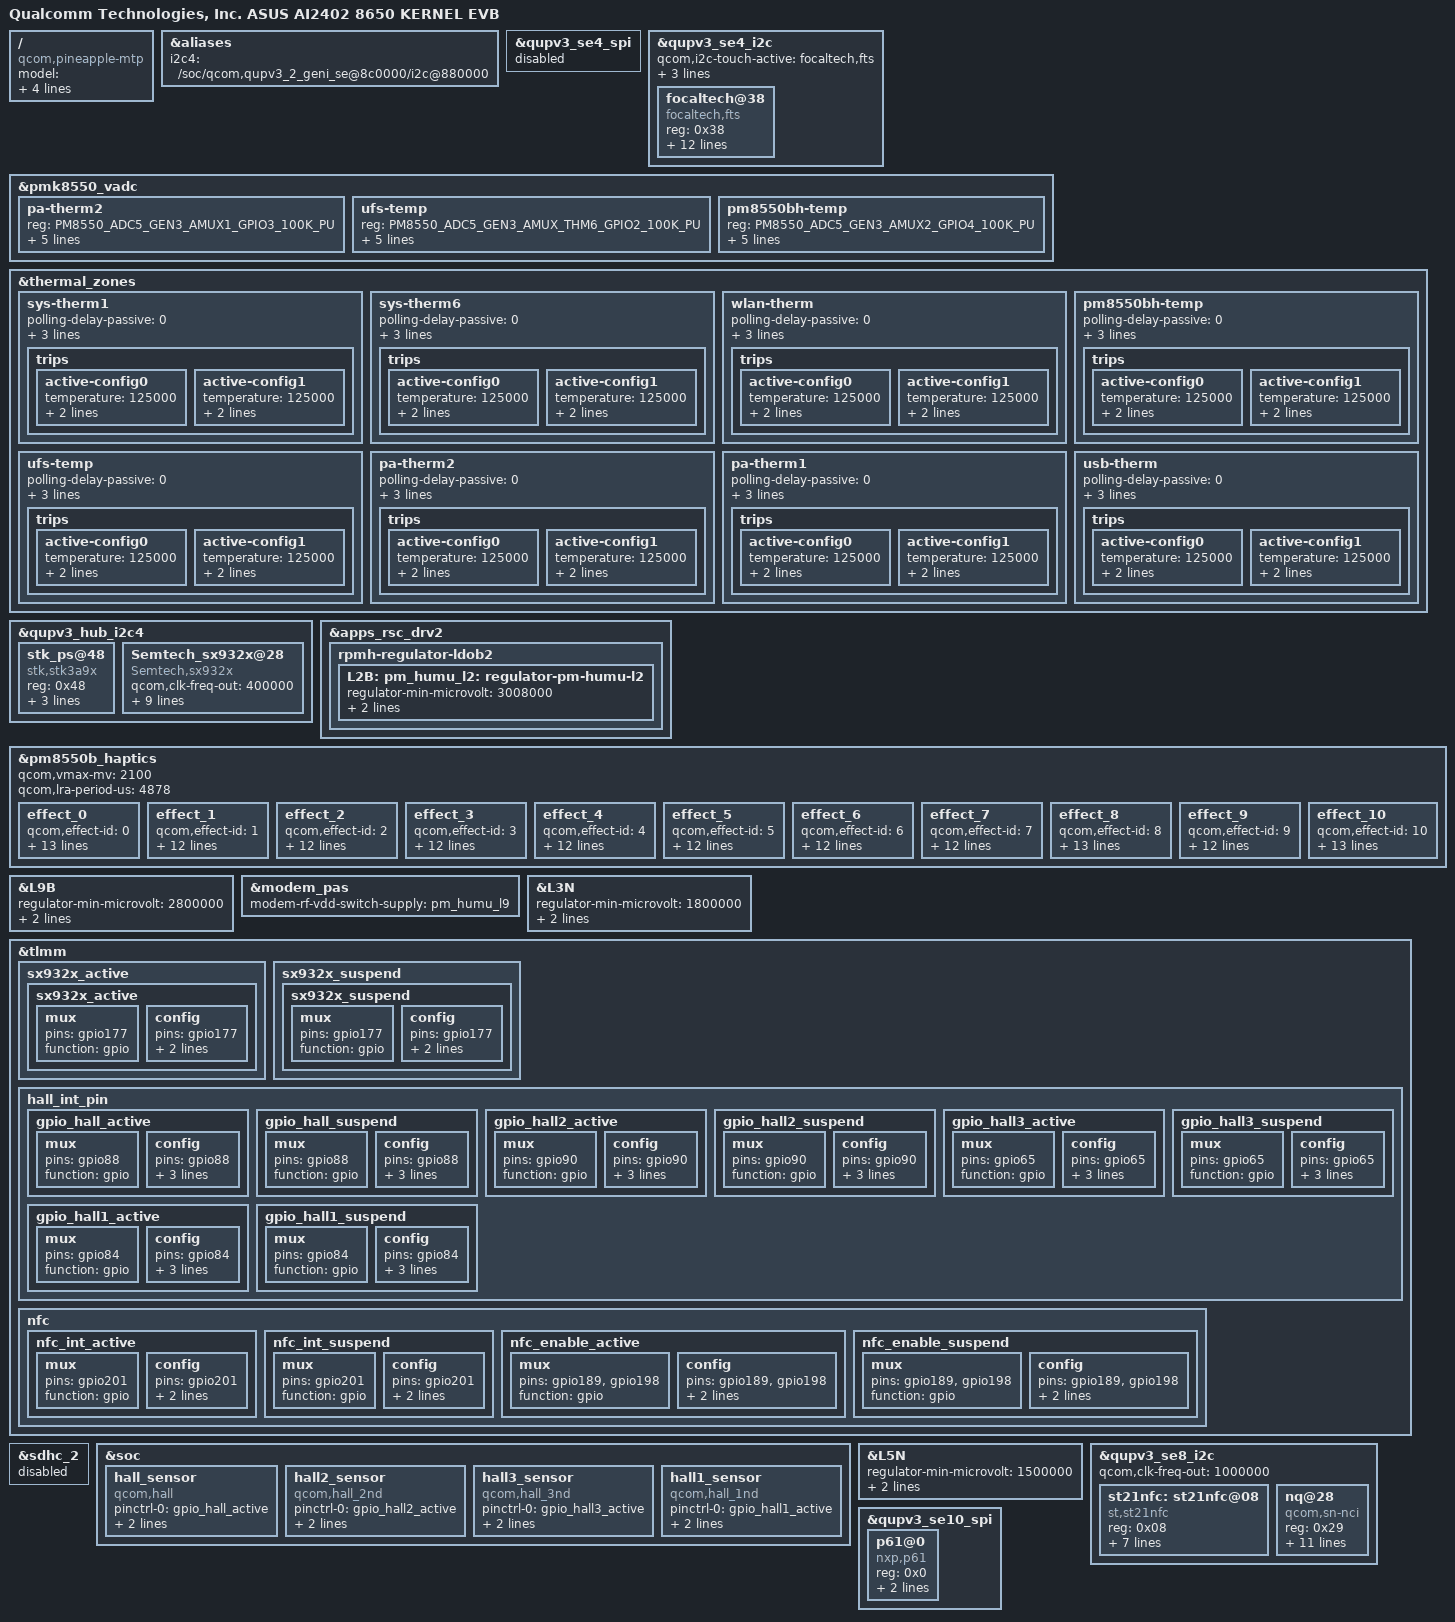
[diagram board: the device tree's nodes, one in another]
/dts-v1/;
/plugin/;

#include "pineapple-mtp.dtsi"

/ {
	model = "Qualcomm Technologies, Inc.  ASUS AI2402 8650 KERNEL EVB ";
	compatible = "qcom,pineapple-mtp", "qcom,pineapple", "qcom,pineapplep-mtp", "qcom,pineapplep", "qcom,mtp";
	qcom,msm-id = <557 0x10000>, <557 0x20000>, <577 0x10000>, <577 0x20000>;
	qcom,board-id = <38 0>;
};

&aliases {
		i2c4 = "/soc/qcom,qupv3_2_geni_se@8c0000/i2c@880000";
};

/*   ====================================
*    overlay for touch - start
*    ====================================
*/


&qupv3_se4_spi {
	status = "disable";
};

&qupv3_se4_i2c {
	#address-cells = <1>;
	#size-cells = <0>;

	status = "ok";
	qcom,i2c-touch-active = "focaltech,fts";
	qcom,touch-active = "focaltech,fts";
	qcom,la-vm;
	qcom,shared;

	focaltech@38 {
		compatible = "focaltech,fts";
		reg = <0x38>;
		interrupt-parent = <&tlmm>;
		interrupts = <162 0x2008>;
		focaltech,reset-gpio = <&tlmm 161 0x00>;
		focaltech,irq-gpio = <&tlmm 162 0x2008>;
		focaltech,max-touch-number = <10>;
		focaltech,display-coords = <0 0 1080 2400>;
		focaltech,touch-type = "primary";

		vdd-supply = <&L14B>;
		vcc_i2c-supply = <&L4B>;

		pinctrl-names = "pmx_ts_active", "pmx_ts_suspend","pmx_ts_release";
		pinctrl-0 = <&ts_active>;
		pinctrl-1 = <&ts_int_suspend &ts_reset_suspend>;
		pinctrl-2 = <&ts_release>;
		//panel = <&dsi_ams667uu07_fhd_plus_dsc_cmd &dsi_ams678_fhd_plus_dsc_cmd &dsi_ams678_er2_fhd_plus_dsc_cmd>
	};
};



&pmk8550_vadc {
	pa-therm2{
		reg = <PM8550_ADC5_GEN3_AMUX1_GPIO3_100K_PU>;
		label = "pa-therm2";
		qcom,ratiometric;
		qcom,hw-settle-time = <200>;
		qcom,pre-scaling = <1 1>;
		qcom,adc-tm-type = <1>;
	};

	ufs-temp {
		reg = <PM8550_ADC5_GEN3_AMUX_THM6_GPIO2_100K_PU>;
		label = "ufs-temp";
		qcom,ratiometric;
		qcom,hw-settle-time = <200>;
		qcom,pre-scaling = <1 1>;
		qcom,adc-tm-type = <1>;
	};

	pm8550bh-temp {
		reg = <PM8550_ADC5_GEN3_AMUX2_GPIO4_100K_PU>;
		label = "pm8550bh-temp";
		qcom,ratiometric;
		qcom,hw-settle-time = <200>;
		qcom,pre-scaling = <1 1>;
		qcom,adc-tm-type = <1>;
	};
};

&thermal_zones{
	sys-therm1 {
		polling-delay-passive = <0>;
		polling-delay = <0>;
		thermal-sensors = <&pmk8550_vadc PM8550_ADC5_GEN3_AMUX_THM1_100K_PU>;
		trips {
			active-config0 {
				temperature = <125000>;
				hysteresis = <1000>;
				type = "passive";
			};

			active-config1 {
				temperature = <125000>;
				hysteresis = <1000>;
				type = "passive";
			};
		};
	};

	sys-therm6 {
		polling-delay-passive = <0>;
		polling-delay = <0>;
		thermal-sensors = <&pmk8550_vadc PM8550_ADC5_GEN3_AMUX_THM2_100K_PU>;
		trips {
			active-config0 {
				temperature = <125000>;
				hysteresis = <1000>;
				type = "passive";
			};

			active-config1 {
				temperature = <125000>;
				hysteresis = <1000>;
				type = "passive";
			};
		};
	};

	wlan-therm {
		polling-delay-passive = <0>;
		polling-delay = <0>;
		thermal-sensors = <&pmk8550_vadc PM8550_ADC5_GEN3_AMUX_THM3_100K_PU>;
		trips {
			active-config0 {
				temperature = <125000>;
				hysteresis = <1000>;
				type = "passive";
			};

			active-config1 {
				temperature = <125000>;
				hysteresis = <1000>;
				type = "passive";
			};
		};
	};

	pm8550bh-temp {
		polling-delay-passive = <0>;
		polling-delay = <0>;
		thermal-sensors = <&pmk8550_vadc PM8550_ADC5_GEN3_AMUX2_GPIO4_100K_PU>;
		trips {
			active-config0 {
				temperature = <125000>;
				hysteresis = <1000>;
				type = "passive";
			};

			active-config1 {
				temperature = <125000>;
				hysteresis = <1000>;
				type = "passive";
			};
		};
	};

	ufs-temp {
		polling-delay-passive = <0>;
		polling-delay = <0>;
		thermal-sensors = <&pmk8550_vadc PM8550_ADC5_GEN3_AMUX_THM6_GPIO2_100K_PU>;
		trips {
			active-config0 {
				temperature = <125000>;
				hysteresis = <1000>;
				type = "passive";
			};

			active-config1 {
				temperature = <125000>;
				hysteresis = <1000>;
				type = "passive";
			};
		};
	};

	pa-therm2 {
		polling-delay-passive = <0>;
		polling-delay = <0>;
		thermal-sensors = <&pmk8550_vadc PM8550_ADC5_GEN3_AMUX1_GPIO3_100K_PU>;
		trips {
			active-config0 {
				temperature = <125000>;
				hysteresis = <1000>;
				type = "passive";
			};

			active-config1 {
				temperature = <125000>;
				hysteresis = <1000>;
				type = "passive";
			};
		};
	};

	pa-therm1 {
		polling-delay-passive = <0>;
		polling-delay = <0>;
		thermal-sensors = <&pmk8550_vadc PM8550_ADC5_GEN3_AMUX_THM4_100K_PU>;
		trips {
			active-config0 {
				temperature = <125000>;
				hysteresis = <1000>;
				type = "passive";
			};

			active-config1 {
				temperature = <125000>;
				hysteresis = <1000>;
				type = "passive";
			};
		};
	};

	usb-therm {
		polling-delay-passive = <0>;
		polling-delay = <0>;
		thermal-sensors = <&pmk8550_vadc PM8550B_ADC5_GEN3_AMUX_THM4_USB_THERM_100K_PU>;
		trips {
			active-config0 {
				temperature = <125000>;
				hysteresis = <1000>;
				type = "passive";
			};

			active-config1 {
				temperature = <125000>;
				hysteresis = <1000>;
				type = "passive";
			};
		};
	};
};







/*   ====================================
*    overlay for touch - end
*    ====================================
*/

/*   ====================================
*    overlay for ALS/PS - start
*    ====================================
*/
&qupv3_hub_i2c4 {
        status = "ok";
        /*
        stk_ps@48 {
            compatible = "stk,stk3a9x";
            reg = <0x48>;
            clocks = <&clock_gcc clk_ln_bb_clk3_pin>;
            clock-names = "ref_clk";                
            stk,irq-gpio = <&tlmm 16 IRQ_TYPE_EDGE_FALLING>;
            stk,als_scale = <1000>;
            //stk,als_is_dri;
            stk,ps_thd_h = <1000>;
            stk,ps_thd_l = <900>;
            stk,ps_ctir = <0>;
            stk,ps_is_dri;
        };
        */
        
        stk_ps@48 {
               compatible = "stk,stk3a9x";
               reg = <0x48>;
               stk,irq-gpio = <&tlmm 64 0x0>;
               vcc_psensor-supply = <&L2B>;
               vcc_psensor_1v8-supply  = <&L1B>;
        };
};

&apps_rsc_drv2 {
	rpmh-regulator-ldob2 {
		L2B: pm_humu_l2: regulator-pm-humu-l2 {
			regulator-min-microvolt = <3008000>;
			regulator-max-microvolt = <3300000>;
			qcom,init-voltage = <3300000>;
		};
	};
};

/*   ====================================
*    overlay for ALS/PS - end
*    ====================================
*/

/*   ====================================
*    overlay for haptic - start
*    ====================================
*/

&pm8550b_haptics {
	qcom,vmax-mv = <2100>;
	qcom,lra-period-us = <4878>;
	status = "ok";

	effect_0 {
		/* CLICK */
		qcom,effect-id = <0>;
		qcom,wf-vmax-mv = <7500>;
		qcom,wf-pattern-data =  <0x0ff  S_PERIOD_T_LRA  0>,
					<0x0ff  S_PERIOD_T_LRA_DIV_2  0>,
					<0x110  S_PERIOD_T_LRA_DIV_2  0>,
					<0x134  S_PERIOD_T_LRA  0>,
					<0x000  S_PERIOD_T_LRA  0>,
					<0x000  S_PERIOD_T_LRA  0>,
					<0x000  S_PERIOD_T_LRA  0>,
					<0x000  S_PERIOD_T_LRA  0>;
		qcom,wf-pattern-period-us = <4878>;
		qcom,wf-brake-pattern = /bits/ 8 <0x0 0x0 0x0>;
		qcom,wf-pattern-preload;
		qcom,wf-auto-res-disable;
	};
	effect_1 {
		/* DOUBLE_CLICK */
		qcom,effect-id = <1>;
		qcom,wf-vmax-mv = <5000>;
		qcom,wf-pattern-data =  <0x0ff  S_PERIOD_T_LRA  0>,
					<0x0ff  S_PERIOD_T_LRA  0>,
					<0x0ff  S_PERIOD_T_LRA  0>,
					<0x0ff  S_PERIOD_T_LRA  0>,
					<0x0ff  S_PERIOD_T_LRA  0>,
					<0x0ff  S_PERIOD_T_LRA  0>,
					<0x12f  S_PERIOD_T_LRA  0>,
					<0x15f  S_PERIOD_T_LRA  0>;
		qcom,wf-pattern-period-us = <4878>;
		qcom,wf-brake-pattern = /bits/ 8 <0x0 0x0 0x0>;
		qcom,wf-auto-res-disable;
	};
	effect_2 {
		/* TICK */
		qcom,effect-id = <2>;
		qcom,wf-vmax-mv = <5000>;
		qcom,wf-pattern-data =  <0x0ff  S_PERIOD_T_LRA  0>,
					<0x0ff  S_PERIOD_T_LRA  0>,
					<0x0ff  S_PERIOD_T_LRA  0>,
					<0x0ff  S_PERIOD_T_LRA  0>,
					<0x0ff  S_PERIOD_T_LRA  0>,
					<0x0ff  S_PERIOD_T_LRA  0>,
					<0x12f  S_PERIOD_T_LRA  0>,
					<0x15f  S_PERIOD_T_LRA  0>;
		qcom,wf-pattern-period-us = <4878>;
		qcom,wf-brake-pattern = /bits/ 8 <0x0 0x0 0x0>;
		qcom,wf-auto-res-disable;
	};
	effect_3 {
		/* THUD */
		qcom,effect-id = <3>;
		qcom,wf-vmax-mv = <5000>;
		qcom,wf-pattern-data =  <0x0ff  S_PERIOD_T_LRA  0>,
					<0x0ff  S_PERIOD_T_LRA  0>,
					<0x0ff  S_PERIOD_T_LRA  0>,
					<0x0ff  S_PERIOD_T_LRA  0>,
					<0x0ff  S_PERIOD_T_LRA  0>,
					<0x0ff  S_PERIOD_T_LRA  0>,
					<0x12f  S_PERIOD_T_LRA  0>,
					<0x15f  S_PERIOD_T_LRA  0>;
		qcom,wf-pattern-period-us = <4878>;
		qcom,wf-brake-pattern = /bits/ 8 <0x0 0x0 0x0>;
		qcom,wf-auto-res-disable;
	};
	effect_4 {
		/* POP */
		qcom,effect-id = <4>;
		qcom,wf-vmax-mv = <5000>;
		qcom,wf-pattern-data =  <0x0ff  S_PERIOD_T_LRA  0>,
					<0x0ff  S_PERIOD_T_LRA  0>,
					<0x0ff  S_PERIOD_T_LRA  0>,
					<0x0ff  S_PERIOD_T_LRA  0>,
					<0x0ff  S_PERIOD_T_LRA  0>,
					<0x0ff  S_PERIOD_T_LRA  0>,
					<0x12f  S_PERIOD_T_LRA  0>,
					<0x15f  S_PERIOD_T_LRA  0>;
		qcom,wf-pattern-period-us = <4878>;
		qcom,wf-brake-pattern = /bits/ 8 <0x0 0x0 0x0>;
		qcom,wf-auto-res-disable;
	};
	effect_5 {
		/* HEAVY CLICK */
		qcom,effect-id = <5>;
		qcom,wf-vmax-mv = <2100>;
		qcom,wf-pattern-data =  <0x0ff  S_PERIOD_T_LRA  0>,
					<0x0ff  S_PERIOD_T_LRA  0>,
					<0x0ff  S_PERIOD_T_LRA  0>,
					<0x0ff  S_PERIOD_T_LRA  0>,
					<0x0ff  S_PERIOD_T_LRA  0>,
					<0x0ff  S_PERIOD_T_LRA  0>,
					<0x12f  S_PERIOD_T_LRA  0>,
					<0x15f  S_PERIOD_T_LRA  0>;
		qcom,wf-pattern-period-us = <4878>;
		qcom,wf-brake-pattern = /bits/ 8 <0x0 0x0 0x0>;
		qcom,wf-auto-res-disable;
	};

	effect_6 {
		/* RINGTONE_1, ID2*/
		qcom,effect-id = <6>;
		qcom,wf-vmax-mv = <4800>;
		qcom,wf-pattern-data =  <0x0ff  S_PERIOD_T_LRA  0>,
					<0x0ff  S_PERIOD_T_LRA_DIV_2  0>,
					<0x110  S_PERIOD_T_LRA_DIV_2  0>,
					<0x134  S_PERIOD_T_LRA  0>,
					<0x000  S_PERIOD_T_LRA  0>,
					<0x000  S_PERIOD_T_LRA  0>,
					<0x000  S_PERIOD_T_LRA  0>,
					<0x000  S_PERIOD_T_LRA  0>;
		qcom,wf-pattern-period-us = <4878>;
		qcom,wf-brake-pattern = /bits/ 8 <0x0 0x0 0x0>;
		qcom,wf-auto-res-disable;
	};
	effect_7 {
		/* RINGTONE_2, ID5 */
		qcom,effect-id = <7>;
		qcom,wf-vmax-mv = <7500>;
		qcom,wf-pattern-data =  <0x0ff  S_PERIOD_T_LRA  0>,
					<0x0ff  S_PERIOD_T_LRA_DIV_2  0>,
					<0x110  S_PERIOD_T_LRA_DIV_2  0>,
					<0x134  S_PERIOD_T_LRA  0>,
					<0x000  S_PERIOD_T_LRA_X_8  0>,
					<0x0ff  S_PERIOD_T_LRA_X_2  0>,
					<0x101  S_PERIOD_T_LRA_DIV_2  0>,
					<0x0122 S_PERIOD_T_LRA  0>;
		qcom,wf-pattern-period-us = <4878>;
		qcom,wf-brake-pattern = /bits/ 8 <0x0 0x0 0x0>;
		qcom,wf-auto-res-disable;
	};
	effect_8 {
		/* RINGTONE_3, ID6-heavy long */
		qcom,effect-id = <8>;
		qcom,wf-vmax-mv = <2100>;
		qcom,wf-pattern-data =  <0x0ff  S_PERIOD_T_LRA_X_8  0>,
					<0x0ff  S_PERIOD_T_LRA_X_8  0>,
					<0x0ff  S_PERIOD_T_LRA_X_8  0>,
					<0x0ff  S_PERIOD_T_LRA_X_8  0>,
					<0x0ff  S_PERIOD_T_LRA_X_8  0>,
					<0x0ff  S_PERIOD_T_LRA_X_8  0>,
					<0x0ff  S_PERIOD_T_LRA_X_8  0>,
					<0x12f  S_PERIOD_T_LRA_X_4  0>;
		qcom,wf-pattern-period-us = <4878>;
		qcom,wf-brake-pattern = /bits/ 8 <0x0 0x0 0x0>;
		qcom,wf-auto-res-disable;
	};
	effect_9 {
		/* RINGTONE_4, ID3*/
		qcom,effect-id = <9>;
		qcom,wf-vmax-mv = <5000>;
		qcom,wf-pattern-data =  <0x100  S_PERIOD_T_LRA  0>,
					<0x100  S_PERIOD_T_LRA_DIV_2  0>,
					<0x000  S_PERIOD_T_LRA  0>,
					<0x000  S_PERIOD_T_LRA  0>,
					<0x000  S_PERIOD_T_LRA  0>,
					<0x000  S_PERIOD_T_LRA  0>,
					<0x000  S_PERIOD_T_LRA  0>,
					<0x000  S_PERIOD_T_LRA  0>;
		qcom,wf-pattern-period-us = <4878>;
		qcom,wf-brake-pattern = /bits/ 8 <0x0 0x0 0x0>;
		qcom,wf-auto-res-disable;
	};
	effect_10 {
		/* RINGTONE_5, ID5-latter half */
		qcom,effect-id = <10>;
		qcom,wf-vmax-mv = <5000>;
		qcom,wf-pattern-data =  <0x0ff  S_PERIOD_T_LRA_X_2  0>,
					<0x101  S_PERIOD_T_LRA_DIV_2  0>,
					<0x0dd  S_PERIOD_T_LRA  0>,
					<0x000  S_PERIOD_T_LRA  0>,
					<0x000  S_PERIOD_T_LRA  0>,
					<0x000  S_PERIOD_T_LRA  0>,
					<0x000  S_PERIOD_T_LRA  0>,
					<0x000  S_PERIOD_T_LRA  0>;
		qcom,wf-pattern-period-us = <4878>;
		qcom,wf-brake-pattern = /bits/ 8 <0x0 0x0 0x0>;
		qcom,wf-auto-res-disable;
	};
};

/*   ====================================
*    overlay for haptic - end
*    ====================================
*/

// ASUS_BSP+++ Phone Antenna

&L9B {
	regulator-min-microvolt = <2800000>;
	regulator-max-microvolt = <2800000>;
	qcom,init-voltage = <2800000>;
};

&modem_pas {
	modem-rf-vdd-switch-supply = <&pm_humu_l9>;
};
// ASUS_BSP--- Phone Antenna


// ASUS_BSP+++ for Audio wcd codec
&L3N {
    regulator-min-microvolt = <1800000>;
    regulator-max-microvolt = <1800000>;
    qcom,init-voltage = <1800000>;
};
// ASUS_BSP--- for Audio wcd codec

//add for sx9325+++++
&qupv3_hub_i2c4 {
	status = "ok";
	Semtech_sx932x@28 {
	compatible = "Semtech,sx932x";
	qcom,clk-freq-out = <400000>;
	reg = <0x28>;
	interrupt-parent = <&tlmm>;
	interrupts = <177 0>;
	pinctrl-names = "sx932x_active","sx932x_suspend";
	pinctrl-0 = <&sx932x_active>;
	pinctrl-1 = <&sx932x_suspend>;

	Semtech,nirq-gpio = <&tlmm 177 0x00>;
	status = "ok";	/**/
	Semtech,reg-num = <45>; /* total registers number to initialize*/
	Semtech,reg-init  = /bits/ 8 < 0x10 0x1C
                                0x11 0x21
                                0x14 0x00
                                0x15 0x00
                                0x20 0x20
                                0x23 0x00
                                0x24 0x47
                                0x26 0x00
                                0x27 0x47
                                0x28 0x39
                                0x29 0x2D
                                0x2A 0x36
                                0x2B 0x07
                                0x2C 0x12
                                0x2D 0x08
                                0x30 0x23
                                0x31 0x08
                                0x32 0x20
                                0x33 0x20
                                0x34 0x0C
                                0x35 0x00
                                0x36 0x8E
                                0x37 0x00
                                0x40 0x00
                                0x41 0x00
                                0x42 0x00
                                0x43 0x00
                                0x44 0x00
                                0x45 0x05
                                0x46 0x00
                                0x47 0x00
                                0x48 0x00
                                0x49 0x00
                                0x4A 0x00
                                0x4B 0x00
                                0x4C 0x00
                                0x50 0x14
                                0x51 0x70
                                0x52 0x20
                                0x02 0x00
                                0x05 0x6F
                                0x06 0x00
                                0x07 0x80
                                0x08 0x01
                                0x03 0x0F>;
	};
};
&tlmm{
	sx932x_active {
		sx932x_active: sx932x_active {
			mux {
				pins = "gpio177";
				function = "gpio";
			};
			config {
				pins = "gpio177";
				bias-pull-up;
				drive-strength = <6>;
			};
		};
	};
	sx932x_suspend {
		sx932x_suspend: sx932x_suspend {
			mux {
				pins = "gpio177";
				function = "gpio";
			};
			config {
				pins = "gpio177";
				bias-disable;
				drive-strength = <2>;
			};
		};
	};
};
//add for sx9325-----

//Hall_sensor +++
//use gpio88 for interrupt pin
&sdhc_2 {
	status = "disable";
};

&soc {
	hall_sensor {
		compatible = "qcom,hall";
		pinctrl-names = "hall_gpio_high","hall_gpio_low";
		//vdd-supply = <&L8C>;
		pinctrl-0 = <&gpio_hall_active>;
		pinctrl-1 = <&gpio_hall_suspend>;
		qcom,hall-gpio = <&tlmm 88 0x0>;
	};

	hall2_sensor {
		compatible = "qcom,hall_2nd";
		pinctrl-names = "hall2_gpio_high","hall2_gpio_low";
		//vdd-supply = <&L8C>;
		pinctrl-0 = <&gpio_hall2_active>;
		pinctrl-1 = <&gpio_hall2_suspend>;
		qcom,hall2-gpio = <&tlmm 90 0x0>;
	};

	hall3_sensor {
		compatible = "qcom,hall_3nd";
		pinctrl-names = "hall3_gpio_high","hall3_gpio_low";
		//vdd-supply = <&L8C>;
		pinctrl-0 = <&gpio_hall3_active>;
		pinctrl-1 = <&gpio_hall3_suspend>;
		qcom,hall3-gpio = <&tlmm 65 0x0>;
	};

	hall1_sensor {
		compatible = "qcom,hall_1nd";
		pinctrl-names = "hall1_gpio_high","hall1_gpio_low";
		//vdd-supply = <&L8C>;
		pinctrl-0 = <&gpio_hall1_active>;
		pinctrl-1 = <&gpio_hall1_suspend>;
		qcom,hall1-gpio = <&tlmm 84 0x0>;
	};
};
//Hall_sensor ---

&tlmm {
//Hall_sensor +++
	hall_int_pin {
		gpio_hall_active: gpio_hall_active {
			mux {
				pins = "gpio88";
				function = "gpio";
			};

			config {
				pins = "gpio88";
				drive-strength = <2>;
				bias-pull-up;
				input-enable;
			};
		};

		gpio_hall_suspend: gpio_hall_suspend {
			mux {
				pins = "gpio88";
				function = "gpio";
			};

			config {
				pins = "gpio88";
				drive-strength = <2>;
				bias-pull-down;
				input-enable;
			};
		};

		gpio_hall2_active: gpio_hall2_active {
			mux {
				pins = "gpio90";
				function = "gpio";
			};

			config {
				pins = "gpio90";
				drive-strength = <2>;
				bias-pull-up;
				input-enable;
			};
		};

		gpio_hall2_suspend: gpio_hall2_suspend {
			mux {
				pins = "gpio90";
				function = "gpio";
			};

			config {
				pins = "gpio90";
				drive-strength = <2>;
				bias-pull-down;
				input-enable;
			};
		};

		gpio_hall3_active: gpio_hall3_active {
			mux {
				pins = "gpio65";
				function = "gpio";
			};

			config {
				pins = "gpio65";
				drive-strength = <2>;
				bias-pull-up;
				input-enable;
			};
		};

		gpio_hall3_suspend: gpio_hall3_suspend {
			mux {
				pins = "gpio65";
				function = "gpio";
			};

			config {
				pins = "gpio65";
				drive-strength = <2>;
				bias-pull-down;
				input-enable;
			};
		};

		gpio_hall1_active: gpio_hall1_active {
			mux {
				pins = "gpio84";
				function = "gpio";
			};

			config {
				pins = "gpio84";
				drive-strength = <2>;
				bias-pull-up;
				input-enable;
			};
		};

		gpio_hall1_suspend: gpio_hall1_suspend {
			mux {
				pins = "gpio84";
				function = "gpio";
			};

			config {
				pins = "gpio84";
				drive-strength = <2>;
				bias-pull-down;
				input-enable;
			};
		};
	};
	//Hall_sensor ---
};

// ASUS_BSP+++ for Panel vdd
&L5N {
    regulator-min-microvolt = <1500000>;
    regulator-max-microvolt = <1800000>;
    qcom,init-voltage = <1500000>;
};
// ASUS_BSP--- for Panel vdd

// ASUS_BSP NFC +++
&qupv3_se8_i2c {
	status = "ok";
	qcom,clk-freq-out = <1000000>;
	#address-cells = <1>;
	#size-cells = <0>;

	st21nfc: st21nfc@08 {
		compatible = "st,st21nfc";
		reg = <0x08>;
		irq-gpios = <&tlmm 201 0x00>;
		reset-gpios = <&tlmm 189 0x00>;
		clkreq-gpios = <&tlmm 198 0x00>;
		interrupt-parent = <&tlmm>;
		interrupts = <201 0>;
		interrupt-names = "nfc_irq";
		pinctrl-names = "nfc_active", "nfc_suspend";
		pinctrl-0 = <&nfc_int_active &nfc_enable_active>;
		pinctrl-1 = <&nfc_int_suspend &nfc_enable_suspend>;
	};

	nq@28 {
		compatible = "qcom,sn-nci";
		reg = <0x29>;
		qcom,sn-irq = <&tlmm 201 0x00>;
		qcom,sn-ven = <&tlmm 189 0x00>;
		qcom,sn-clkreq = <&tlmm 198 0x00>;
		qcom,sn-szone = "enable";
		#qcom,sn-vdd-1p8-supply = <&L3C>;
		#qcom,sn-vdd-1p8-voltage = <1200000 1200000>;
		#qcom,sn-vdd-1p8-current = <157000>;
		interrupt-parent = <&tlmm>;
		interrupts = <201 0>;
		interrupt-names = "nfc_irq";
		pinctrl-names = "nfc_active", "nfc_suspend";
		pinctrl-0 = <&nfc_int_active &nfc_enable_active>;
		pinctrl-1 = <&nfc_int_suspend &nfc_enable_suspend>;
	};
};

&qupv3_se10_spi {
	status = "ok";
	p61@0 {
		compatible = "nxp,p61";
		reg = <0x0>;
		spi-max-frequency = <20000000>;
		nxp,nfcc = "4-0029";
	};
};

&tlmm {
	nfc {
		nfc_int_active: nfc_int_active {
			/* active state */
			mux {
				/* NFC Read Interrupt */
				pins = "gpio201";
				function = "gpio";
			};

			config {
				pins = "gpio201";
				drive-strength = <2>; /* 2 MA */
				bias-pull-down;
			};
		};

		nfc_int_suspend: nfc_int_suspend {
			/* sleep state */
			mux {
				/* NFC Read Interrupt */
				pins = "gpio201";
				function = "gpio";
			};

			config {
				pins = "gpio201";
				drive-strength = <2>; /* 2 MA */
				bias-pull-down;
			};
		};

		nfc_enable_active: nfc_enable_active {
			mux {
				/* Enable, and Clock request gpios */
				pins = "gpio189", "gpio198";
				function = "gpio";
			};

			config {
				pins = "gpio189", "gpio198";
				drive-strength = <2>; /* 2 MA */
				bias-disable;
			};
		};

		nfc_enable_suspend: nfc_enable_suspend {
			mux {
				pins = "gpio189", "gpio198";
				function = "gpio";
			};

			config {
				pins = "gpio189", "gpio198";
				drive-strength = <2>; /* 2 MA */
				bias-disable;
			};
		};
	}; //nfc
}; //tlmm
// ASUS_BSP NFC ---
